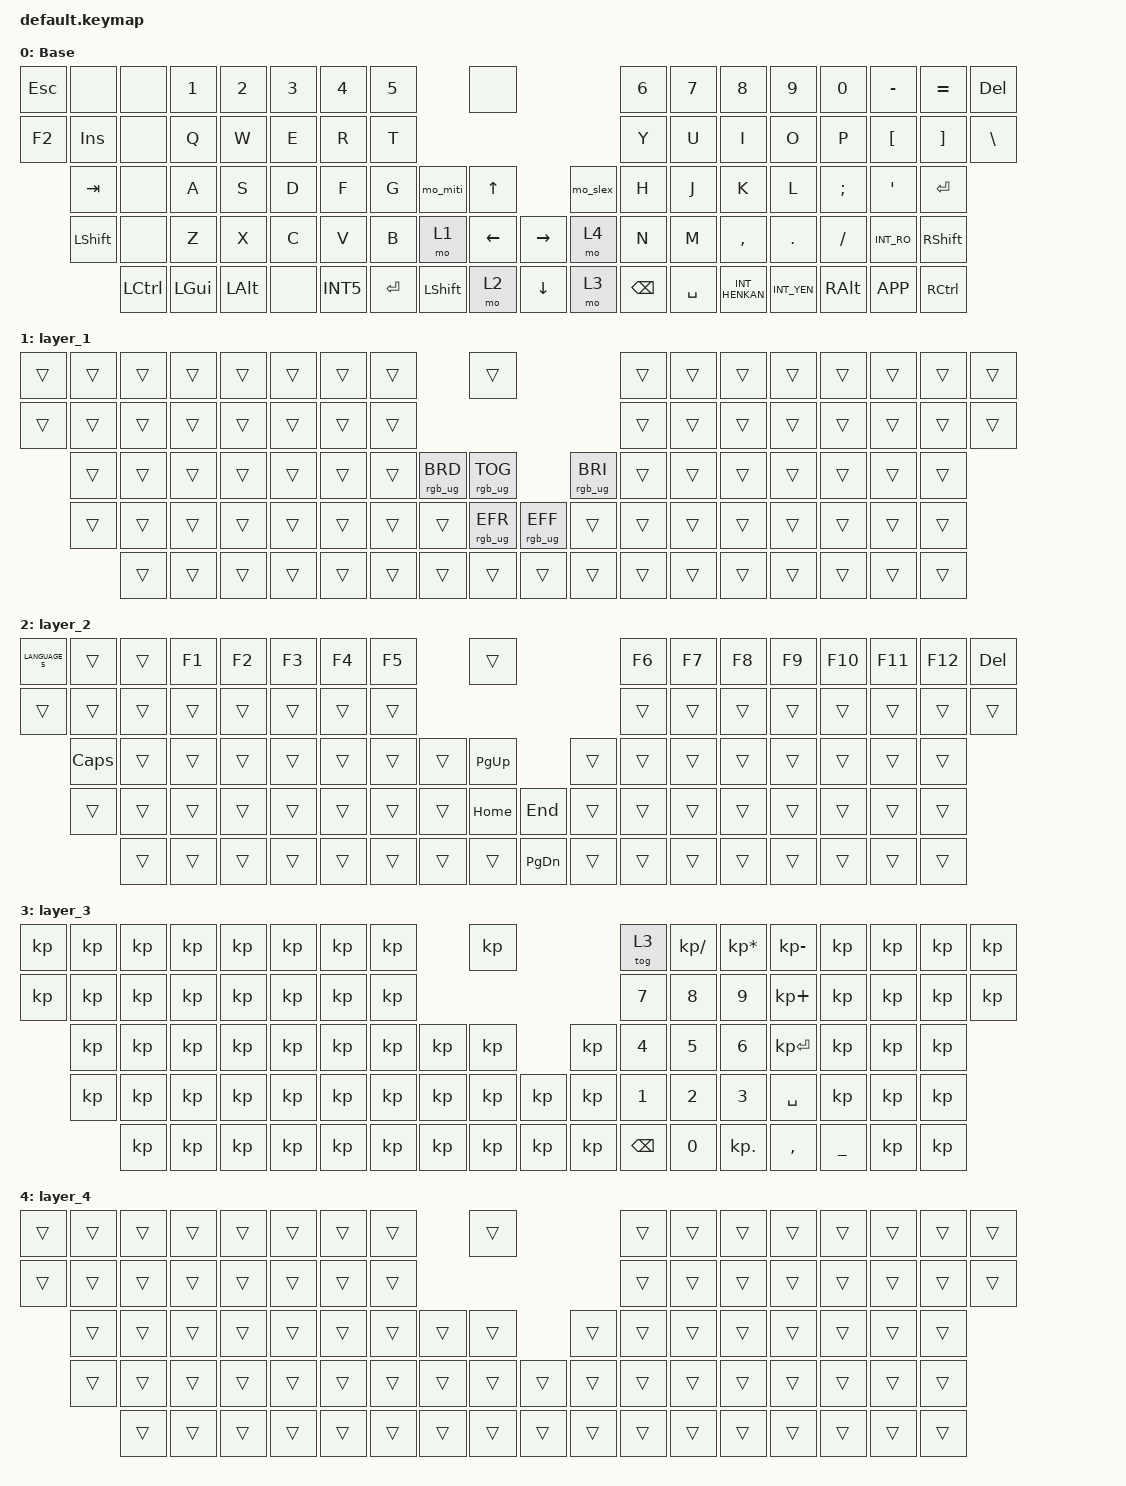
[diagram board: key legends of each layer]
#include <dt-bindings/zmk/modifiers.h>
#include <dt-bindings/zmk/mouse.h>
#include <behaviors/rgbled_widget.dtsi>  //キースイッチバッテリーウィジット
#include <behaviors.dtsi>
#include <dt-bindings/zmk/keys.h>
#include <dt-bindings/zmk/rgb.h>

/ {
    behaviors {
        // 通常時は「?」、Shift時は「!」

        mo_slex: slash_exclamation {
            compatible = "zmk,behavior-mod-morph";
            #binding-cells = <0>;
            bindings = <&kp LS(SLASH)>, <&kp LS(NUMBER_1)>;

            mods = <(MOD_LSFT|MOD_RSFT)>;
            label = "? !";
        };

        // 通常時は「-」、Shift時は「~」

        mo_miti: minus_tilde {
            compatible = "zmk,behavior-mod-morph";
            #binding-cells = <0>;
            bindings = <&kp MINUS>, <&kp LS(EQUAL)>;

            mods = <(MOD_LSFT|MOD_RSFT)>;
            label = "- ~";
        };
    };

    keymap {
        compatible = "zmk,keymap";

        default_layer {
            display-name = "Base";

            // |  0 |  1 |  2 |  3 |  4 |  5 |  6 |  7 |           |  8 |         | |  9 | 10 | 11 | 12 | 13 | 14 | 15 | 16 | 
            // | 17 | 18 | 19 | 20 | 21 | 22 | 23 | 24 |                          | | 25 | 26 | 27 | 28 | 29 | 30 | 31 | 32 |
            //      | 33 | 34 | 35 | 36 | 37 | 38 | 39 |      | 40 | 41 | 42 |    | | 43 | 44 | 45 | 46 | 47 | 48 | 49 |
            //      | 50 | 51 | 52 | 53 | 54 | 55 | 56 | | 57 | 58 |    | 59 | 60 | | 61 | 62 | 63 | 64 | 65 | 66 | 67 |
            //           | 68 | 69 | 70 | 71 | 72 | 73 | | 74 | 75 | 76 | 77 | 78 | | 79 | 80 | 81 | 82 | 83 | 84 |

            bindings = <
&kp ESCAPE  &none           &none      &kp N1        &kp N2        &kp N3  &kp N4    &kp N5                          &none                               &kp N6     &kp N7          &kp N8       &kp N9    &kp N0     &kp MINUS   &kp EQUAL        &kp DELETE
&kp F2      &kp INSERT      &none      &kp Q         &kp W         &kp E   &kp R     &kp T                                                               &kp Y      &kp U           &kp I        &kp O     &kp P      &kp LBKT    &kp RBKT         &kp BSLH
            &kp TAB         &none      &kp A         &kp S         &kp D   &kp F     &kp G      &mo_miti             &kp UP               &mo_slex       &kp H      &kp J           &kp K        &kp L     &kp SEMI   &kp SQT     &kp ENTER
            &kp LEFT_SHIFT  &none      &kp Z         &kp X         &kp C   &kp V     &kp B      &mo 1      &kp LEFT            &kp RIGHT  &mo 4          &kp N      &kp M           &kp COMMA    &kp DOT   &kp FSLH   &kp INT_RO  &kp RIGHT_SHIFT
                            &kp LCTRL  &kp LEFT_GUI  &kp LEFT_ALT  &none   &kp INT5  &kp ENTER  &kp LSHFT  &mo 2     &kp DOWN  &mo 3      &kp BACKSPACE  &kp SPACE  &kp INT_HENKAN  &kp INT_YEN  &kp RALT  &kp K_APP  &kp RCTRL
            >;

            //サンプル &rgb_ug RGB_BRI  &rgb_ug RGB_BRD  &rgb_ug RGB_TOG  &rgb_ug RGB_EFR &ind_bat

            sensor-bindings = <&inc_dec_kp K_SCROLL_DOWN K_SCROLL_UP>;      //sensor-bindings = <BINDING [CW_KEY] [CCW_KEY]>;
        };

        layer_1 {
            bindings = <
&trans  &trans  &trans  &trans  &trans  &trans  &trans  &trans                                    &trans                                             &trans  &trans  &trans  &trans  &trans  &trans  &trans  &trans
&trans  &trans  &trans  &trans  &trans  &trans  &trans  &trans                                                                                       &trans  &trans  &trans  &trans  &trans  &trans  &trans  &trans
        &trans  &trans  &trans  &trans  &trans  &trans  &trans  &rgb_ug RGB_BRD                   &rgb_ug RGB_TOG                   &rgb_ug RGB_BRI  &trans  &trans  &trans  &trans  &trans  &trans  &trans
        &trans  &trans  &trans  &trans  &trans  &trans  &trans  &trans           &rgb_ug RGB_EFR                   &rgb_ug RGB_EFF  &trans           &trans  &trans  &trans  &trans  &trans  &trans  &trans
                &trans  &trans  &trans  &trans  &trans  &trans  &trans           &trans           &trans           &trans           &trans           &trans  &trans  &trans  &trans  &trans  &trans
            >;

            sensor-bindings = <&inc_dec_kp 0 0>;
        };

        layer_2 {
            bindings = <
&kp LANGUAGE_5  &trans    &trans  &kp F1  &kp F2  &kp F3  &kp F4  &kp F5                    &trans                          &kp F6  &kp F7  &kp F8  &kp F9  &kp F10  &kp F11  &kp F12  &kp DEL
&trans          &trans    &trans  &trans  &trans  &trans  &trans  &trans                                                    &trans  &trans  &trans  &trans  &trans   &trans   &trans   &trans
                &kp CAPS  &trans  &trans  &trans  &trans  &trans  &trans  &trans            &kp PAGE_UP             &trans  &trans  &trans  &trans  &trans  &trans   &trans   &trans
                &trans    &trans  &trans  &trans  &trans  &trans  &trans  &trans  &kp HOME                 &kp END  &trans  &trans  &trans  &trans  &trans  &trans   &trans   &trans
                          &trans  &trans  &trans  &trans  &trans  &trans  &trans  &trans    &kp PAGE_DOWN  &trans   &trans  &trans  &trans  &trans  &trans  &trans   &trans
            >;
        };

        layer_3 {
            bindings = <
&kp  &kp  &kp  &kp  &kp  &kp  &kp  &kp            &kp                      &tog 3  &kp KP_SLASH  &kp KP_ASTERISK  &kp KP_MINUS  &kp  &kp  &kp  &kp
&kp  &kp  &kp  &kp  &kp  &kp  &kp  &kp                                     &kp N7  &kp N8        &kp N9           &kp KP_PLUS   &kp  &kp  &kp  &kp
     &kp  &kp  &kp  &kp  &kp  &kp  &kp  &kp       &kp       &kp            &kp N4  &kp N5        &kp N6           &kp KP_ENTER  &kp  &kp  &kp
     &kp  &kp  &kp  &kp  &kp  &kp  &kp  &kp  &kp       &kp  &kp            &kp N1  &kp N2        &kp N3           &kp SPACE     &kp  &kp  &kp
          &kp  &kp  &kp  &kp  &kp  &kp  &kp  &kp  &kp  &kp  &kp BACKSPACE  &kp N0  &kp KP_DOT    &kp COMMA        &kp UNDER     &kp  &kp
            >;
        };

        layer_4 {
            bindings = <
&trans  &trans  &trans  &trans  &trans  &trans  &trans  &trans                  &trans                  &trans  &trans  &trans  &trans  &trans  &trans  &trans  &trans
&trans  &trans  &trans  &trans  &trans  &trans  &trans  &trans                                          &trans  &trans  &trans  &trans  &trans  &trans  &trans  &trans
        &trans  &trans  &trans  &trans  &trans  &trans  &trans  &trans          &trans          &trans  &trans  &trans  &trans  &trans  &trans  &trans  &trans
        &trans  &trans  &trans  &trans  &trans  &trans  &trans  &trans  &trans          &trans  &trans  &trans  &trans  &trans  &trans  &trans  &trans  &trans
                &trans  &trans  &trans  &trans  &trans  &trans  &trans  &trans  &trans  &trans  &trans  &trans  &trans  &trans  &trans  &trans  &trans
            >;
        };
    };
};
